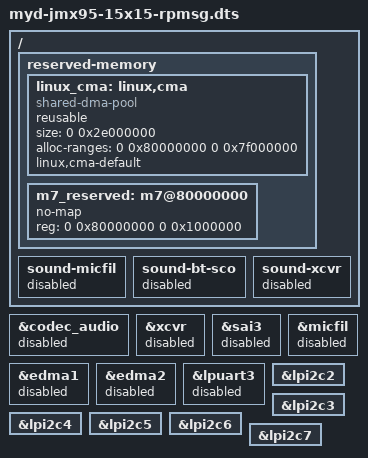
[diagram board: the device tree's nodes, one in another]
// SPDX-License-Identifier: (GPL-2.0+ OR MIT)
/*
 * Copyright 2024 NXP
 * Copyright 2026 MYIR
 */

#include "myd-jmx95-15x15.dts"

/ {
	reserved-memory {
		linux_cma: linux,cma {
			compatible = "shared-dma-pool";
			reusable;
			size = <0 0x2e000000>;
			alloc-ranges = <0 0x80000000 0 0x7f000000>;
			linux,cma-default;
		};

		m7_reserved: m7@80000000 {
			no-map;
			reg = <0 0x80000000 0 0x1000000>;
		};

	};

	sound-micfil {
		status = "disabled";
	};

	sound-bt-sco {
		status = "disabled";
	};

	sound-xcvr {
		status = "disabled";
	};

};

&codec_audio {
	status = "disabled";
};

&xcvr {
	status = "disabled";
};

&sai3 {
	status = "disabled";
};

&micfil {
	status = "disabled";
};

&edma1 {
	status = "disabled";
};

&edma2{
	status = "disabled";
};

&lpuart3 {
	status = "disabled";
};

&lpi2c2 {
	/delete-property/ dmas;
	/delete-property/ dma-names;
};

&lpi2c3 {
	/delete-property/ dmas;
	/delete-property/ dma-names;
};

&lpi2c4 {
	/delete-property/ dmas;
	/delete-property/ dma-names;
};

&lpi2c5 {
	/delete-property/ dmas;
	/delete-property/ dma-names;
};

&lpi2c6 {
	/delete-property/ dmas;
	/delete-property/ dma-names;
};

&lpi2c7 {
	/delete-property/ dmas;
	/delete-property/ dma-names;
};
